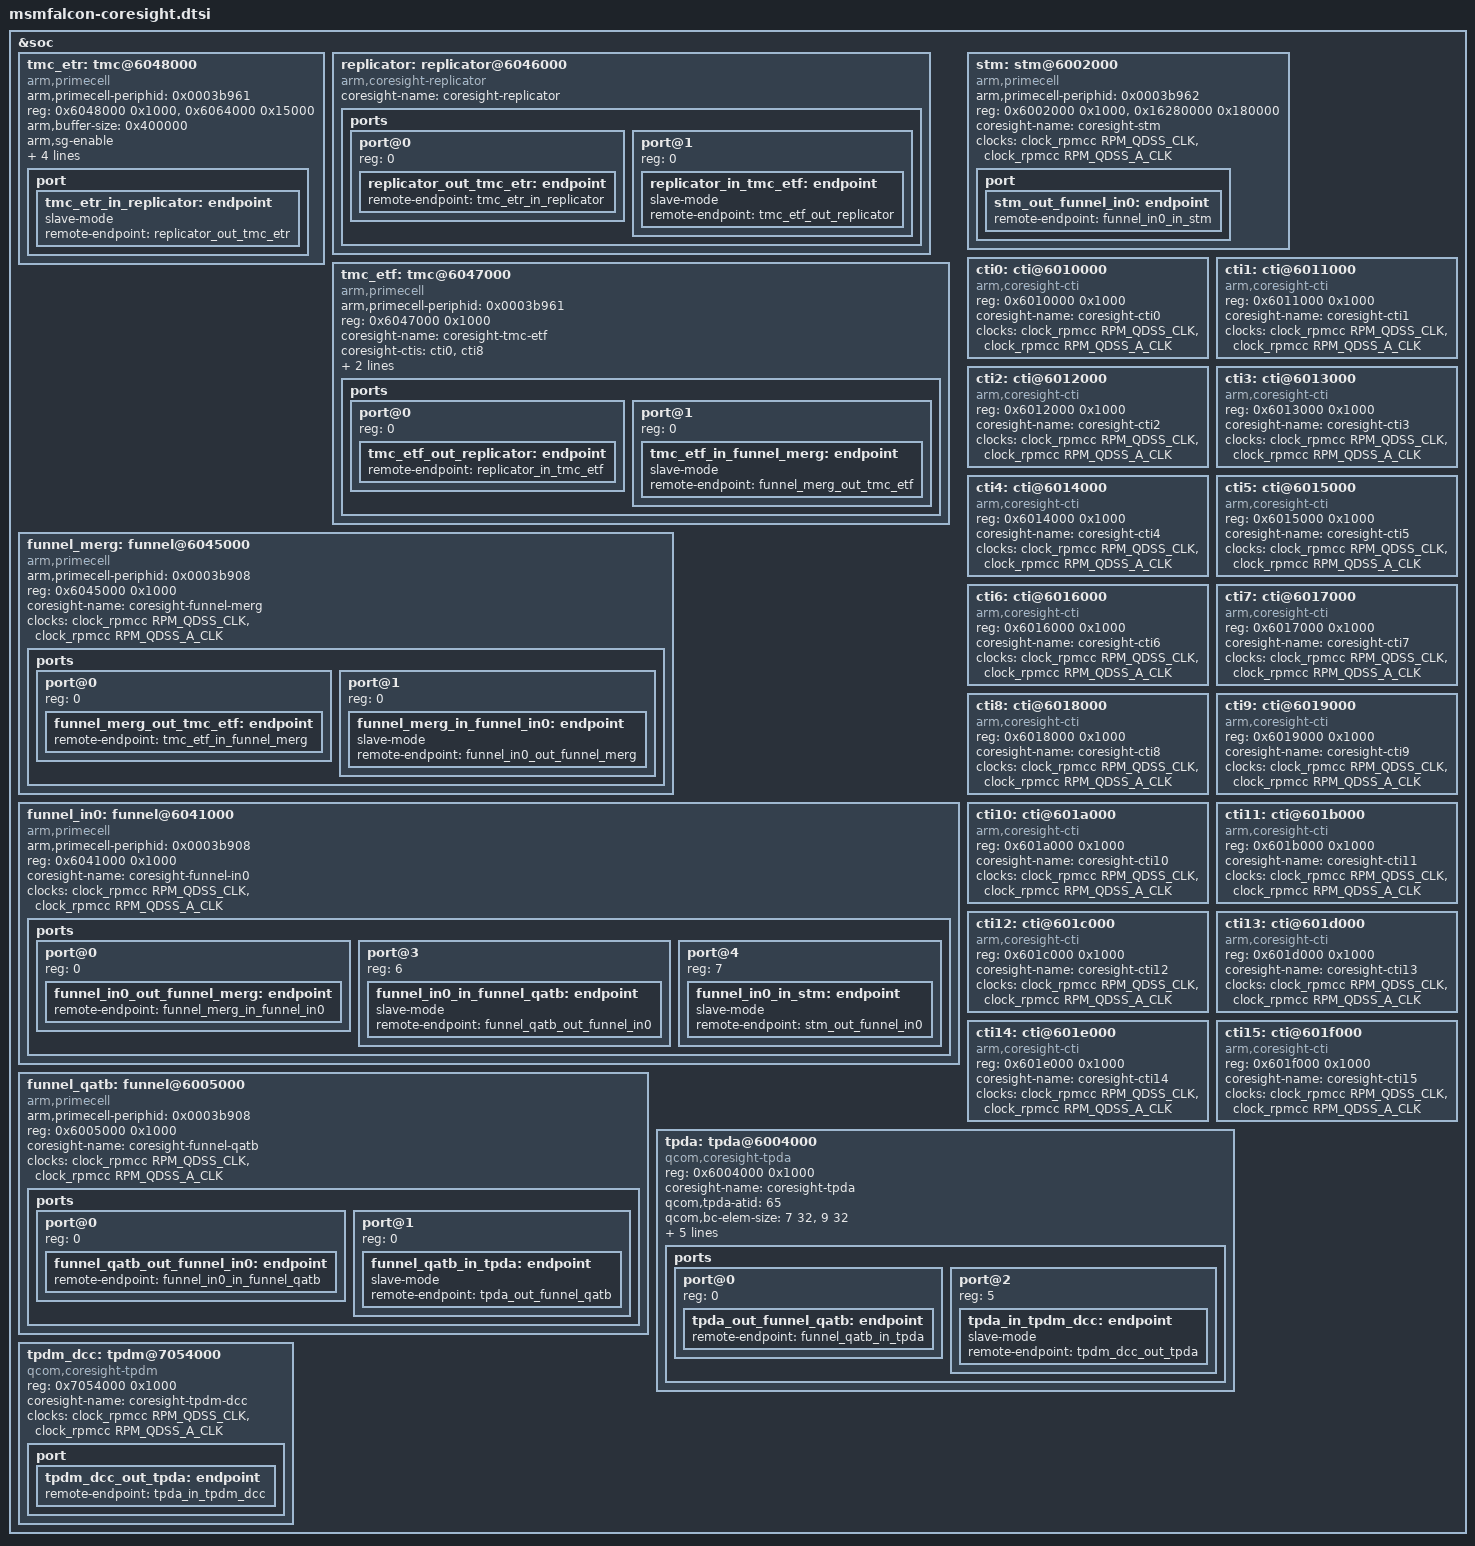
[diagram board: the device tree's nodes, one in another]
/* Copyright (c) 2016, The Linux Foundation. All rights reserved.
 *
 * This program is free software; you can redistribute it and/or modify
 * it under the terms of the GNU General Public License version 2 and
 * only version 2 as published by the Free Software Foundation.
 *
 * This program is distributed in the hope that it will be useful,
 * but WITHOUT ANY WARRANTY; without even the implied warranty of
 * MERCHANTABILITY or FITNESS FOR A PARTICULAR PURPOSE.  See the
 * GNU General Public License for more details.
 */

#include <dt-bindings/clock/qcom,gcc-msmfalcon.h>
#include <dt-bindings/clock/qcom,gpu-msmfalcon.h>
#include <dt-bindings/clock/qcom,mmcc-msmfalcon.h>

&soc {
	tmc_etr: tmc@6048000 {
		compatible = "arm,primecell";
		arm,primecell-periphid = <0x0003b961>;

		reg = <0x6048000 0x1000>,
		      <0x6064000 0x15000>;
		reg-names = "tmc-base", "bam-base";

		arm,buffer-size = <0x400000>;
		arm,sg-enable;

		coresight-ctis = <&cti0 &cti8>;

		coresight-name = "coresight-tmc-etr";

		clocks = <&clock_rpmcc RPM_QDSS_CLK>,
			 <&clock_rpmcc RPM_QDSS_A_CLK>;
		clock-names = "apb_pclk", "core_a_clk";

		port{
			tmc_etr_in_replicator: endpoint {
				slave-mode;
				remote-endpoint = <&replicator_out_tmc_etr>;
			};
		};
	};

	replicator: replicator@6046000 {
		compatible = "arm,coresight-replicator";

		coresight-name = "coresight-replicator";

		ports{
			#address-cells = <1>;
			#size-cells = <0>;

			port@0 {
				reg = <0>;
				replicator_out_tmc_etr:endpoint {
					remote-endpoint =
						<&tmc_etr_in_replicator>;
				};
			};
			port@1 {
				reg = <0>;
				replicator_in_tmc_etf:endpoint {
					slave-mode;
					remote-endpoint =
						<&tmc_etf_out_replicator>;
				};
			};
		};
	};

	tmc_etf: tmc@6047000 {
		compatible = "arm,primecell";
		arm,primecell-periphid = <0x0003b961>;

		reg = <0x6047000 0x1000>;
		reg-names = "tmc-base";

		coresight-name = "coresight-tmc-etf";

		coresight-ctis = <&cti0 &cti8>;

		clocks = <&clock_rpmcc RPM_QDSS_CLK>,
			 <&clock_rpmcc RPM_QDSS_A_CLK>;
		clock-names = "apb_pclk", "core_a_clk";

		ports{
			#address-cells = <1>;
			#size-cells = <0>;

			port@0 {
				reg = <0>;
				tmc_etf_out_replicator:endpoint {
					remote-endpoint =
						<&replicator_in_tmc_etf>;
				};
			};
			port@1 {
				reg = <0>;
				tmc_etf_in_funnel_merg:endpoint {
					slave-mode;
					remote-endpoint =
						<&funnel_merg_out_tmc_etf>;
				};
			};
		};
	};

	funnel_merg: funnel@6045000 {
		compatible = "arm,primecell";
		arm,primecell-periphid = <0x0003b908>;

		reg = <0x6045000 0x1000>;
		reg-names = "funnel-base";

		coresight-name = "coresight-funnel-merg";

		clocks = <&clock_rpmcc RPM_QDSS_CLK>,
			 <&clock_rpmcc RPM_QDSS_A_CLK>;
		clock-names = "apb_pclk", "core_a_clk";

		ports {
			#address-cells = <1>;
			#size-cells = <0>;

			port@0 {
				reg = <0>;
				funnel_merg_out_tmc_etf:endpoint {
					remote-endpoint =
						<&tmc_etf_in_funnel_merg>;
				};
			};
			port@1 {
				reg = <0>;
				funnel_merg_in_funnel_in0:endpoint {
					slave-mode;
					remote-endpoint =
						<&funnel_in0_out_funnel_merg>;
				};
			};
		};
	};

	funnel_in0: funnel@6041000 {
		compatible = "arm,primecell";
		arm,primecell-periphid = <0x0003b908>;

		reg = <0x6041000 0x1000>;
		reg-names = "funnel-base";

		coresight-name = "coresight-funnel-in0";

		clocks = <&clock_rpmcc RPM_QDSS_CLK>,
			 <&clock_rpmcc RPM_QDSS_A_CLK>;
		clock-names = "apb_pclk", "core_a_clk";

		ports {
			#address-cells = <1>;
			#size-cells = <0>;

			port@0 {
				reg = <0>;
				funnel_in0_out_funnel_merg: endpoint {
					remote-endpoint =
						<&funnel_merg_in_funnel_in0>;
				};
			};
			port@3 {
				reg = <6>;
				funnel_in0_in_funnel_qatb: endpoint {
					slave-mode;
					remote-endpoint =
						<&funnel_qatb_out_funnel_in0>;
				};
			};
			port@4 {
				reg = <7>;
				funnel_in0_in_stm: endpoint {
					slave-mode;
					remote-endpoint = <&stm_out_funnel_in0>;
				};
			};
		};
	};

	stm: stm@6002000 {
		compatible = "arm,primecell";
		arm,primecell-periphid = <0x0003b962>;

		reg = <0x6002000 0x1000>,
		      <0x16280000 0x180000>;
		reg-names = "stm-base", "stm-data-base";

		coresight-name = "coresight-stm";

		clocks = <&clock_rpmcc RPM_QDSS_CLK>,
			 <&clock_rpmcc RPM_QDSS_A_CLK>;
		clock-names = "apb_pclk", "core_a_clk";

		port{
			stm_out_funnel_in0: endpoint {
				remote-endpoint = <&funnel_in0_in_stm>;
			};
		};
	};

	cti0: cti@6010000 {
		compatible = "arm,coresight-cti";
		reg = <0x6010000 0x1000>;
		reg-names = "cti-base";

		coresight-name = "coresight-cti0";

		clocks = <&clock_rpmcc RPM_QDSS_CLK>,
			 <&clock_rpmcc RPM_QDSS_A_CLK>;
		clock-names = "core_clk", "core_a_clk";
	};

	cti1: cti@6011000 {
		compatible = "arm,coresight-cti";
		reg = <0x6011000 0x1000>;
		reg-names = "cti-base";

		coresight-name = "coresight-cti1";

		clocks = <&clock_rpmcc RPM_QDSS_CLK>,
			 <&clock_rpmcc RPM_QDSS_A_CLK>;
		clock-names = "core_clk", "core_a_clk";
	};

	cti2: cti@6012000 {
		compatible = "arm,coresight-cti";
		reg = <0x6012000 0x1000>;
		reg-names = "cti-base";

		coresight-name = "coresight-cti2";

		clocks = <&clock_rpmcc RPM_QDSS_CLK>,
			 <&clock_rpmcc RPM_QDSS_A_CLK>;
		clock-names = "core_clk", "core_a_clk";
	};

	cti3: cti@6013000 {
		compatible = "arm,coresight-cti";
		reg = <0x6013000 0x1000>;
		reg-names = "cti-base";

		coresight-name = "coresight-cti3";

		clocks = <&clock_rpmcc RPM_QDSS_CLK>,
			 <&clock_rpmcc RPM_QDSS_A_CLK>;
		clock-names = "core_clk", "core_a_clk";
	};

	cti4: cti@6014000 {
		compatible = "arm,coresight-cti";
		reg = <0x6014000 0x1000>;
		reg-names = "cti-base";

		coresight-name = "coresight-cti4";

		clocks = <&clock_rpmcc RPM_QDSS_CLK>,
			 <&clock_rpmcc RPM_QDSS_A_CLK>;
		clock-names = "core_clk", "core_a_clk";
	};

	cti5: cti@6015000 {
		compatible = "arm,coresight-cti";
		reg = <0x6015000 0x1000>;
		reg-names = "cti-base";

		coresight-name = "coresight-cti5";

		clocks = <&clock_rpmcc RPM_QDSS_CLK>,
			 <&clock_rpmcc RPM_QDSS_A_CLK>;
		clock-names = "core_clk", "core_a_clk";
	};

	cti6: cti@6016000 {
		compatible = "arm,coresight-cti";
		reg = <0x6016000 0x1000>;
		reg-names = "cti-base";

		coresight-name = "coresight-cti6";

		clocks = <&clock_rpmcc RPM_QDSS_CLK>,
			 <&clock_rpmcc RPM_QDSS_A_CLK>;
		clock-names = "core_clk", "core_a_clk";
	};

	cti7: cti@6017000 {
		compatible = "arm,coresight-cti";
		reg = <0x6017000 0x1000>;
		reg-names = "cti-base";

		coresight-name = "coresight-cti7";

		clocks = <&clock_rpmcc RPM_QDSS_CLK>,
			 <&clock_rpmcc RPM_QDSS_A_CLK>;
		clock-names = "core_clk", "core_a_clk";
	};

	cti8: cti@6018000 {
		compatible = "arm,coresight-cti";
		reg = <0x6018000 0x1000>;
		reg-names = "cti-base";

		coresight-name = "coresight-cti8";

		clocks = <&clock_rpmcc RPM_QDSS_CLK>,
			 <&clock_rpmcc RPM_QDSS_A_CLK>;
		clock-names = "core_clk", "core_a_clk";
	};

	cti9: cti@6019000 {
		compatible = "arm,coresight-cti";
		reg = <0x6019000 0x1000>;
		reg-names = "cti-base";

		coresight-name = "coresight-cti9";

		clocks = <&clock_rpmcc RPM_QDSS_CLK>,
			 <&clock_rpmcc RPM_QDSS_A_CLK>;
		clock-names = "core_clk", "core_a_clk";
	};

	cti10: cti@601a000 {
		compatible = "arm,coresight-cti";
		reg = <0x601a000 0x1000>;
		reg-names = "cti-base";

		coresight-name = "coresight-cti10";

		clocks = <&clock_rpmcc RPM_QDSS_CLK>,
			 <&clock_rpmcc RPM_QDSS_A_CLK>;
		clock-names = "core_clk", "core_a_clk";
	};

	cti11: cti@601b000 {
		compatible = "arm,coresight-cti";
		reg = <0x601b000 0x1000>;
		reg-names = "cti-base";

		coresight-name = "coresight-cti11";

		clocks = <&clock_rpmcc RPM_QDSS_CLK>,
			 <&clock_rpmcc RPM_QDSS_A_CLK>;
		clock-names = "core_clk", "core_a_clk";
	};

	cti12: cti@601c000 {
		compatible = "arm,coresight-cti";
		reg = <0x601c000 0x1000>;
		reg-names = "cti-base";

		coresight-name = "coresight-cti12";

		clocks = <&clock_rpmcc RPM_QDSS_CLK>,
			 <&clock_rpmcc RPM_QDSS_A_CLK>;
		clock-names = "core_clk", "core_a_clk";
	};

	cti13: cti@601d000 {
		compatible = "arm,coresight-cti";
		reg = <0x601d000 0x1000>;
		reg-names = "cti-base";

		coresight-name = "coresight-cti13";

		clocks = <&clock_rpmcc RPM_QDSS_CLK>,
			 <&clock_rpmcc RPM_QDSS_A_CLK>;
		clock-names = "core_clk", "core_a_clk";
	};

	cti14: cti@601e000 {
		compatible = "arm,coresight-cti";
		reg = <0x601e000 0x1000>;
		reg-names = "cti-base";

		coresight-name = "coresight-cti14";

		clocks = <&clock_rpmcc RPM_QDSS_CLK>,
			 <&clock_rpmcc RPM_QDSS_A_CLK>;
		clock-names = "core_clk", "core_a_clk";
	};

	cti15: cti@601f000 {
		compatible = "arm,coresight-cti";
		reg = <0x601f000 0x1000>;
		reg-names = "cti-base";

		coresight-name = "coresight-cti15";

		clocks = <&clock_rpmcc RPM_QDSS_CLK>,
			 <&clock_rpmcc RPM_QDSS_A_CLK>;
		clock-names = "core_clk", "core_a_clk";
	};

	funnel_qatb: funnel@6005000 {
		compatible = "arm,primecell";
		arm,primecell-periphid = <0x0003b908>;

		reg = <0x6005000 0x1000>;
		reg-names = "funnel-base";

		coresight-name = "coresight-funnel-qatb";

		clocks = <&clock_rpmcc RPM_QDSS_CLK>,
			 <&clock_rpmcc RPM_QDSS_A_CLK>;
		clock-names = "apb_pclk", "core_a_clk";

		ports {
			#address-cells = <1>;
			#size-cells = <0>;

			port@0 {
				reg = <0>;
				funnel_qatb_out_funnel_in0: endpoint {
					remote-endpoint =
					    <&funnel_in0_in_funnel_qatb>;
				};
			};
			port@1 {
				reg = <0>;
				funnel_qatb_in_tpda: endpoint {
					slave-mode;
					remote-endpoint =
						<&tpda_out_funnel_qatb>;
				};
			};
		};
	};

	tpda: tpda@6004000 {
		compatible = "qcom,coresight-tpda";
		reg = <0x6004000 0x1000>;
		reg-names = "tpda-base";

		coresight-name = "coresight-tpda";

		qcom,tpda-atid = <65>;
		qcom,bc-elem-size = <7 32>,
				    <9 32>;
		qcom,tc-elem-size = <3 32>,
				    <6 32>,
				    <9 32>;
		qcom,dsb-elem-size = <7 32>,
				     <9 32>;
		qcom,cmb-elem-size = <3 32>,
				     <4 32>,
				     <5 32>,
				     <9 64>;

		clocks = <&clock_rpmcc RPM_QDSS_CLK>,
			 <&clock_rpmcc RPM_QDSS_A_CLK>;
		clock-names = "core_clk", "core_a_clk";

		ports {
			#address-cells = <1>;
			#size-cells = <0>;
			port@0 {
				reg = <0>;
				tpda_out_funnel_qatb: endpoint {
					remote-endpoint =
						<&funnel_qatb_in_tpda>;
				};
			};
			port@2 {
				reg = <5>;
				tpda_in_tpdm_dcc: endpoint {
					slave-mode;
					remote-endpoint =
						<&tpdm_dcc_out_tpda>;
				};
			};
		};
	};

	tpdm_dcc: tpdm@7054000 {
		compatible = "qcom,coresight-tpdm";
		reg = <0x7054000 0x1000>;
		reg-names = "tpdm-base";

		coresight-name = "coresight-tpdm-dcc";

		clocks = <&clock_rpmcc RPM_QDSS_CLK>,
			 <&clock_rpmcc RPM_QDSS_A_CLK>;
		clock-names = "core_clk", "core_a_clk";

		port{
			tpdm_dcc_out_tpda: endpoint {
				remote-endpoint = <&tpda_in_tpdm_dcc>;
			};
		};
	};
};
